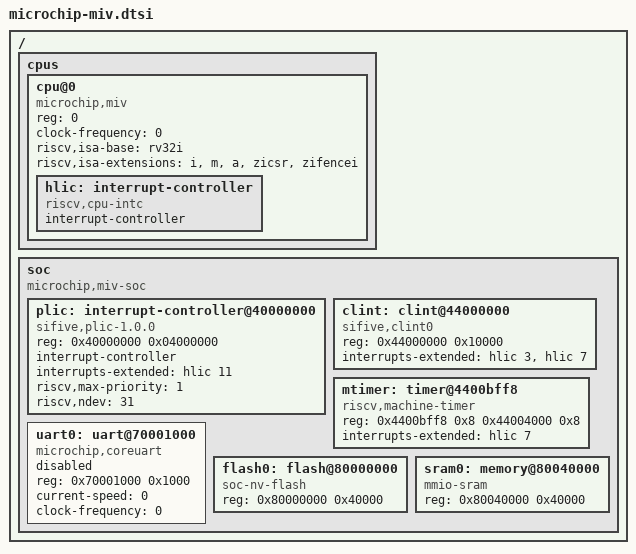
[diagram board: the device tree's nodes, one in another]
/*
 * Copyright (c) 2018 Linaro Limited
 *
 * SPDX-License-Identifier: Apache-2.0
 */

/ {
	#address-cells = <1>;
	#size-cells = <1>;

	cpus {
		#address-cells = <1>;
		#size-cells = <0>;

		cpu@0 {
			compatible = "microchip,miv", "riscv";
			reg = <0>;
			clock-frequency = <0>;
			device_type = "cpu";
			riscv,isa-base = "rv32i";
			riscv,isa-extensions = "i", "m", "a", "zicsr", "zifencei";

			hlic: interrupt-controller {
				compatible = "riscv,cpu-intc";
				#address-cells = <0>;
				#interrupt-cells = <1>;
				interrupt-controller;
			};
		};
	};

	soc {
		compatible = "microchip,miv-soc", "simple-bus";
		ranges;
		#address-cells = <1>;
		#size-cells = <1>;

		plic: interrupt-controller@40000000 {
			compatible = "sifive,plic-1.0.0";
			reg = <0x40000000 0x04000000>;
			#address-cells = <0>;
			#interrupt-cells = <2>;
			interrupt-controller;
			interrupts-extended = <&hlic 11>;
			riscv,max-priority = <1>;
			riscv,ndev = <31>;
		};

		clint: clint@44000000 {
			compatible = "sifive,clint0";
			reg = <0x44000000 0x10000>;
			interrupts-extended = <&hlic 3>, <&hlic 7>;
		};

		mtimer: timer@4400bff8 {
			compatible = "riscv,machine-timer";
			reg = <0x4400bff8 0x8 0x44004000 0x8>;
			interrupts-extended = <&hlic 7>;
			reg-names = "mtime", "mtimecmp";
		};

		uart0: uart@70001000 {
			compatible = "microchip,coreuart";
			reg = <0x70001000 0x1000>;
			current-speed = <0>;
			clock-frequency = <0>;
			status = "disabled";
		};

		flash0: flash@80000000 {
			compatible = "soc-nv-flash";
			reg = <0x80000000 0x40000>;
		};

		sram0: memory@80040000 {
			compatible = "mmio-sram";
			reg = <0x80040000 0x40000>;
		};
	};
};
